# MKW38A4 register map
Vendor: NXP Semiconductors; Series: Kinetis_W; File version: 1.6
CPU: CM0PLUS r0p0, little endian, no MPU, no FPU, VTOR, 2 interrupt priority bits
Registers are 32-bit, read-write, no defined reset value unless marked. A register's access mark holds for its fields unless they carry their own. Offsets are from the block's base; [hi:lo] are bit positions; {n}, {i} and the like mark numbered series; 'fields as' and 'values as' point back to an identical list.

## DMA0 — DMA
Base 0x40008000
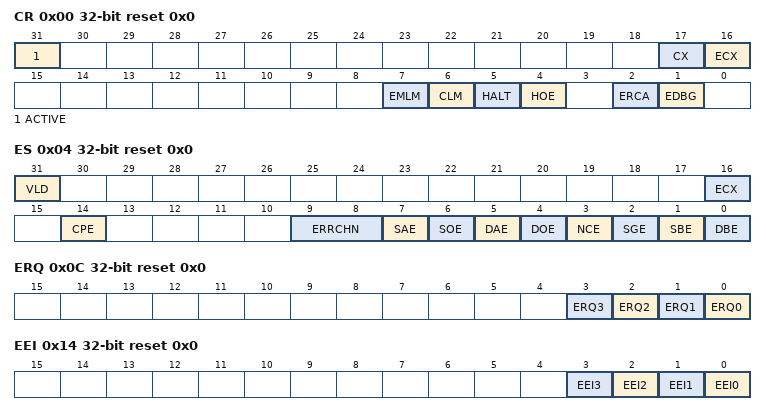
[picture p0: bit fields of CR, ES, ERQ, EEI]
0x00 CR reset 0x0 — Control
  [31] ACTIVE ro — DMA Active Status
    0=eDMA is idle; 1=eDMA is executing a channel
  [17] CX — Cancel Transfer
    0=Normal operation; 1=Cancel the remaining data transfer
  [16] ECX — Error Cancel Transfer
    0=Normal operation; 1=Cancel the remaining data transfer
  [7] EMLM — Enable Minor Loop Mapping
    0=Disabled; 1=Enabled
  [6] CLM — Continuous Link Mode
    0=Continuous link mode is off; 1=Continuous link mode is on
  [5] HALT — Halt DMA Operations
    0=Normal operation; 1=DMA operations halted
  [4] HOE — Halt On Error
    0=Normal operation; 1=Error causes HALT field to be automatically set to 1
  [2] ERCA — Enable Round Robin Channel Arbitration
    0=Fixed priority arbitration; 1=Round robin arbitration
  [1] EDBG — Enable Debug
    0=. When in debug mode, the DMA continues to operate.; 1=Assertion of system debug control input is effective
0x04 ES ro reset 0x0 — Error Status
  [31] VLD — Logical OR of all ERR status fields
    0=No ERR fields are 1; 1=At least one ERR field is 1, indicating a valid error exists that has not been cleared
  [16] ECX — Transfer Canceled
    0=No canceled transfers; 1=The most-recently recorded entry was a canceled transfer initiated by the error cancel transfer field
  [14] CPE — Channel Priority Error
    0=No channel priority error; 1=The most-recently recorded error was a configuration error in the channel priorities. Channel priorities are not unique.
  [9:8] ERRCHN — Error Channel Number or Canceled Channel Number
  [7] SAE — Source Address Error
    0=No source address configuration error; 1=The most-recently recorded error was a configuration error detected in the TCDn_SADDR field. TCDn_SADDR is inconsistent with TCDn_ATTR[SSIZE].
  [6] SOE — Source Offset Error
    0=No source offset configuration error; 1=The most-recently recorded error was a configuration error detected in the TCDn_SOFF field. TCDn_SOFF is inconsistent with TCDn_ATTR[SSIZE].
  [5] DAE — Destination Address Error
    0=No destination address configuration error; 1=The most-recently recorded error was a configuration error detected in the TCDn_DADDR field. TCDn_DADDR is inconsistent with TCDn_ATTR[DSIZE].
  [4] DOE — Destination Offset Error
    0=No destination offset configuration error; 1=The most-recently recorded error was a configuration error detected in the TCDn_DOFF field. TCDn_DOFF is inconsistent with TCDn_ATTR[DSIZE].
  [3] NCE — NBYTES/CITER Configuration Error
    0=No NBYTES/CITER configuration error; 1=The most-recently recorded error was a configuration error detected in the TCDn_NBYTES or TCDn_CITER fields. TCDn_NBYTES is not a multiple of TCDn_ATTR[SSIZE] and TCDn_ATTR[DSIZE], or TCDn_CITER[CITER] is equal to zero, or TCDn_CITER[ELINK] is not equal to TCDn_BITER[ELINK].
  [2] SGE — Scatter/Gather Configuration Error
    0=No scatter/gather configuration error; 1=The most-recently recorded error was a configuration error detected in the TCDn_DLASTSGA field
  [1] SBE — Source Bus Error
    0=No source bus error; 1=The most-recently recorded error was a bus error on a source read
  [0] DBE — Destination Bus Error
    0=No destination bus error; 1=The most-recently recorded error was a bus error on a destination write
0x0C ERQ reset 0x0 — Enable Request
  [n] ERQ{n} (n=0..3) — Enable DMA Request {n}
    0=The DMA request signal for channel {n} is disabled; 1=The DMA request signal for channel {n} is enabled
0x14 EEI reset 0x0 — Enable Error Interrupt
  [n] EEI{n} (n=0..3) — Enable Error Interrupt {n}
    0=The error signal for channel {n} does not generate an error interrupt; 1=The assertion of the error signal for channel {n} generates an error interrupt request
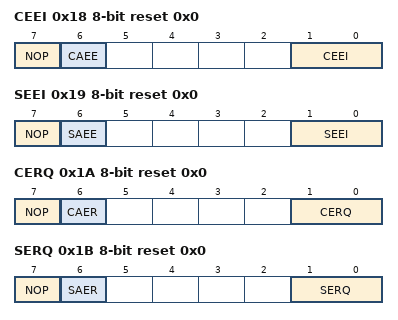
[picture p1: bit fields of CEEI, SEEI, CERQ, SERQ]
0x18 CEEI 8-bit reset 0x0 — Clear Enable Error Interrupt
  [7] NOP — No Op Enable
    0=Normal operation; 1=No operation, ignore the other fields in this register
  [6] CAEE — Clear All Enable Error Interrupts
    0=Write 0 only to the EEI field specified in the CEEI field; 1=Write 0 to all fields in EEI
  [1:0] CEEI — Clear Enable Error Interrupt
0x19 SEEI 8-bit reset 0x0 — Set Enable Error Interrupt
  [7] NOP — No Op Enable
    values as CEEI.NOP
  [6] SAEE — Set All Enable Error Interrupts
    0=Write 1 only to the EEI field specified in the SEEI field; 1=Writes 1 to all fields in EEI
  [1:0] SEEI — Set Enable Error Interrupt
0x1A CERQ 8-bit reset 0x0 — Clear Enable Request
  [7] NOP — No Op Enable
    values as CEEI.NOP
  [6] CAER — Clear All Enable Requests
    0=Write 0 to only the ERQ field specified in the CERQ field; 1=Write 0 to all fields in ERQ
  [1:0] CERQ — Clear Enable Request
0x1B SERQ 8-bit reset 0x0 — Set Enable Request
  [7] NOP — No Op Enable
    values as CEEI.NOP
  [6] SAER — Set All Enable Requests
    0=Write 1 to only the ERQ field specified in the SERQ field; 1=Write 1 to all fields in ERQ
  [1:0] SERQ — Set Enable Request
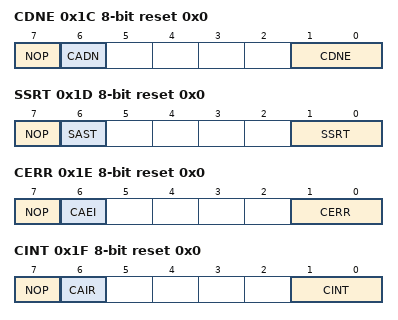
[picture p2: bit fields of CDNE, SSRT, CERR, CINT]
0x1C CDNE 8-bit reset 0x0 — Clear DONE Status Bit
  [7] NOP — No Op Enable
    0=Normal operation; 1=No operation; all other fields in this register are ignored
  [6] CADN — Clears All DONE fields
    0=Writes 0 to only the TCDn_CSR[DONE] field specified in the CDNE field; 1=Writes 0 to all bits in TCDn_CSR[DONE]
  [1:0] CDNE — Clear DONE field
0x1D SSRT 8-bit reset 0x0 — Set START Bit
  [7] NOP — No Op Enable
    values as CDNE.NOP
  [6] SAST — Set All START fields (activates all channels)
    0=Write 1 to only the TCDn_CSR[START] field specified in the SSRT field; 1=Write 1 to all bits in TCDn_CSR[START]
  [1:0] SSRT — Set START field
0x1E CERR 8-bit reset 0x0 — Clear Error
  [7] NOP — No Op Enable
    values as CDNE.NOP
  [6] CAEI — Clear All Error Indicators
    0=Write 0 to only the ERR field specified in the CERR field; 1=Write 0 to all fields in ERR
  [1:0] CERR — Clear Error Indicator
0x1F CINT 8-bit reset 0x0 — Clear Interrupt Request
  [7] NOP — No Op Enable
    values as CDNE.NOP
  [6] CAIR — Clear All Interrupt Requests
    0=Clear only the INT field specified in the CINT field; 1=Clear all bits in INT
  [1:0] CINT — Clear Interrupt Request
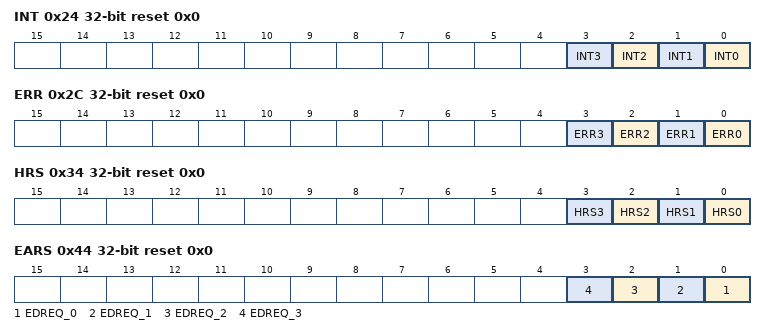
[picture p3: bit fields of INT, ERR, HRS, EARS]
0x24 INT reset 0x0 — Interrupt Request
  [n] INT{n} (n=0..3) — Interrupt Request {n}
    1=The interrupt request for channel {n} is cleared
0x2C ERR reset 0x0 — Error
  [all] fields
    0=No error in this channel has occurred; 1=An error in this channel has occurred
  [n] ERR{n} (n=0..3) — Error In Channel {n}
0x34 HRS ro reset 0x0 — Hardware Request Status
  [n] HRS{n} (n=0..3) — Hardware Request Status Channel {n}
    0=A hardware service request for channel {n} is not present; 1=A hardware service request for channel {n} is present
0x44 EARS reset 0x0 — Enable Asynchronous Request in Stop
  [n] EDREQ_{n} (n=0..3) — Enable asynchronous DMA request in stop mode for channel {n}.
    0=Disable asynchronous DMA request for channel {n}; 1=Enable asynchronous DMA request for channel {n}
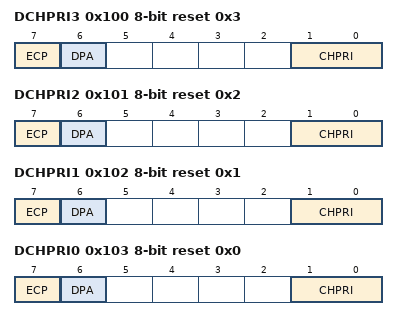
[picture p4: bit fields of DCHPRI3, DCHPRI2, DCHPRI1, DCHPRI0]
0x100 DCHPRI3 8-bit reset 0x3 — Channel Priority
  [7] ECP — Enable Channel Preemption. This field resets to 0.
    0=Channel n cannot be suspended by a higher priority channel's service request; 1=Channel n can be temporarily suspended by the service request of a higher priority channel
  [6] DPA — Disable Preempt Ability. This field resets to 0.
    0=Channel n can suspend a lower priority channel; 1=Channel n cannot suspend any channel, regardless of channel priority
  [1:0] CHPRI — Channel n Arbitration Priority
0x101 DCHPRI2 8-bit reset 0x2 — Channel Priority
  fields as DCHPRI3
0x102 DCHPRI1 8-bit reset 0x1 — Channel Priority
  fields as DCHPRI3
0x103 DCHPRI0 8-bit reset 0x0 — Channel Priority
  fields as DCHPRI3
{0x1000+0x20*i} TCD{i}_SADDR (i=0..3) — TCD Source Address
  [31:0] SADDR — Source Address
{0x1004+0x20*i} TCD{i}_SOFF 16-bit (i=0..3) — TCD Signed Source Address Offset
  [15:0] SOFF — Source address signed offset
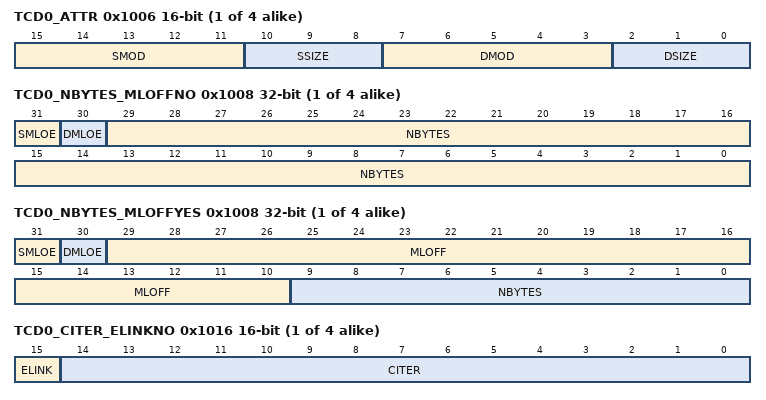
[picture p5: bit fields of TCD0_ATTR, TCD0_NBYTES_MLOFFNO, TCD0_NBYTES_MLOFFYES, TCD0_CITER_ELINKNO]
{0x1006+0x20*i} TCD{i}_ATTR 16-bit (i=0..3) — TCD Transfer Attributes
  [15:11] SMOD — Source Address Modulo
    0=Source address modulo feature is disabled
  [10:8] SSIZE — Source data transfer size
    0=8-bit; 1=16-bit; 2=32-bit; 4=16-byte; 5=32-byte
  [7:3] DMOD — Destination Address Modulo
  [2:0] DSIZE — Destination data transfer size
{0x1008+0x20*i} TCD{i}_NBYTES_MLNO (DMA0 view) (i=0..3) — TCD Minor Byte Count (Minor Loop Mapping Disabled)
  [31:0] NBYTES — Minor Byte Transfer Count
{0x1008+0x20*i} TCD{i}_NBYTES_MLOFFNO (DMA0 view) (i=0..3) — TCD Signed Minor Loop Offset (Minor Loop Mapping Enabled and Offset Disabled)
  [31] SMLOE — Source Minor Loop Offset Enable
    0=The minor loop offset is not applied to the SADDR; 1=The minor loop offset is applied to the SADDR
  [30] DMLOE — Destination Minor Loop Offset Enable
    0=The minor loop offset is not applied to the DADDR; 1=The minor loop offset is applied to the DADDR
  [29:0] NBYTES — Minor Byte Transfer Count
{0x1008+0x20*i} TCD{i}_NBYTES_MLOFFYES (DMA0 view) (i=0..3) — TCD Signed Minor Loop Offset (Minor Loop Mapping and Offset Enabled)
  [31] SMLOE — Source Minor Loop Offset Enable
    values as TCD0_NBYTES_MLOFFNO.SMLOE
  [30] DMLOE — Destination Minor Loop Offset Enable
    values as TCD0_NBYTES_MLOFFNO.DMLOE
  [29:10] MLOFF — If SMLOE or DMLOE is set, this field represents a sign-extended offset applied to the source or destination address to form the next-state value after the minor loop completes.
  [9:0] NBYTES — Minor Byte Transfer Count
{0x100C+0x20*i} TCD{i}_SLAST (i=0..3) — TCD Last Source Address Adjustment
  [31:0] SLAST — Last Source Address Adjustment
{0x1010+0x20*i} TCD{i}_DADDR (i=0..3) — TCD Destination Address
  [31:0] DADDR — Destination Address
{0x1014+0x20*i} TCD{i}_DOFF 16-bit (i=0..3) — TCD Signed Destination Address Offset
  [15:0] DOFF — Destination Address Signed Offset
{0x1016+0x20*i} TCD{i}_CITER_ELINKNO 16-bit (DMA0 view) (i=0..3) — TCD Current Minor Loop Link, Major Loop Count (Channel Linking Disabled)
  [15] ELINK — Enable channel-to-channel linking on minor-loop complete
    0=Channel-to-channel linking is disabled; 1=Channel-to-channel linking is enabled
  [14:0] CITER — Current Major Iteration Count
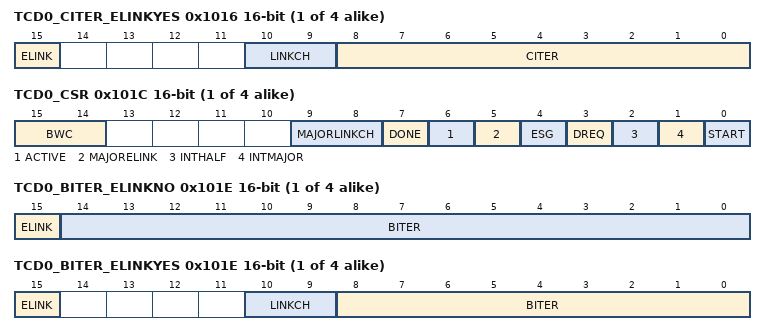
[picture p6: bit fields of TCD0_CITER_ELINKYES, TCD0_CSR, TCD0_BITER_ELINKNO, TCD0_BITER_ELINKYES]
{0x1016+0x20*i} TCD{i}_CITER_ELINKYES 16-bit (DMA0 view) (i=0..3) — TCD Current Minor Loop Link, Major Loop Count (Channel Linking Enabled)
  [15] ELINK — Enable channel-to-channel linking on minor-loop complete
    values as TCD0_CITER_ELINKNO.ELINK
  [10:9] LINKCH — Minor Loop Link Channel Number
  [8:0] CITER — Current Major Iteration Count
{0x1018+0x20*i} TCD{i}_DLASTSGA (i=0..3) — TCD Last Destination Address Adjustment/Scatter Gather Address
  [31:0] DLASTSGA — Destination last address adjustment, or next memory address transfer control descriptor for channel (scatter/gather)
{0x101C+0x20*i} TCD{i}_CSR 16-bit (i=0..3) — TCD Control and Status
  [15:14] BWC — Bandwidth Control
    0=No eDMA engine stalls; 2=eDMA engine stalls for 4 cycles after each R/W; 3=eDMA engine stalls for 8 cycles after each R/W
  [9:8] MAJORLINKCH — Major Loop Link Channel Number
  [7] DONE — Channel Done
  [6] ACTIVE ro — Channel Active
  [5] MAJORELINK — Enable channel-to-channel linking on major loop complete
    1=Channel-to-channel linking is disabled
  [4] ESG — Enable Scatter/Gather Processing
    0=The current channel's TCD is normal format; 1=The current channel's TCD specifies a scatter gather format
  [3] DREQ — Disable Request
    0=The channel's ERQ field is not affected; 1=The channel's ERQ field is cleared when the major loop is complete
  [2] INTHALF — Enable an interrupt when major counter is half complete.
    0=Half-point interrupt is disabled; 1=Half-point interrupt is enabled
  [1] INTMAJOR — Enable an interrupt when major iteration count completes.
    0=End of major loop interrupt is disabled; 1=End of major loop interrupt is enabled
  [0] START — Channel Start
    0=Channel is not explicitly started; 1=Channel is explicitly started via a software initiated service request
{0x101E+0x20*i} TCD{i}_BITER_ELINKNO 16-bit (DMA0 view) (i=0..3) — TCD Beginning Minor Loop Link, Major Loop Count (Channel Linking Disabled)
  [15] ELINK — Enables channel-to-channel linking on minor loop complete
    values as TCD0_CITER_ELINKNO.ELINK
  [14:0] BITER — Starting Major Iteration Count
{0x101E+0x20*i} TCD{i}_BITER_ELINKYES 16-bit (DMA0 view) (i=0..3) — TCD Beginning Minor Loop Link, Major Loop Count (Channel Linking Enabled)
  [15] ELINK — Enables channel-to-channel linking on minor loop complete
    values as TCD0_CITER_ELINKNO.ELINK
  [10:9] LINKCH — Link Channel Number
  [8:0] BITER — Starting major iteration count
